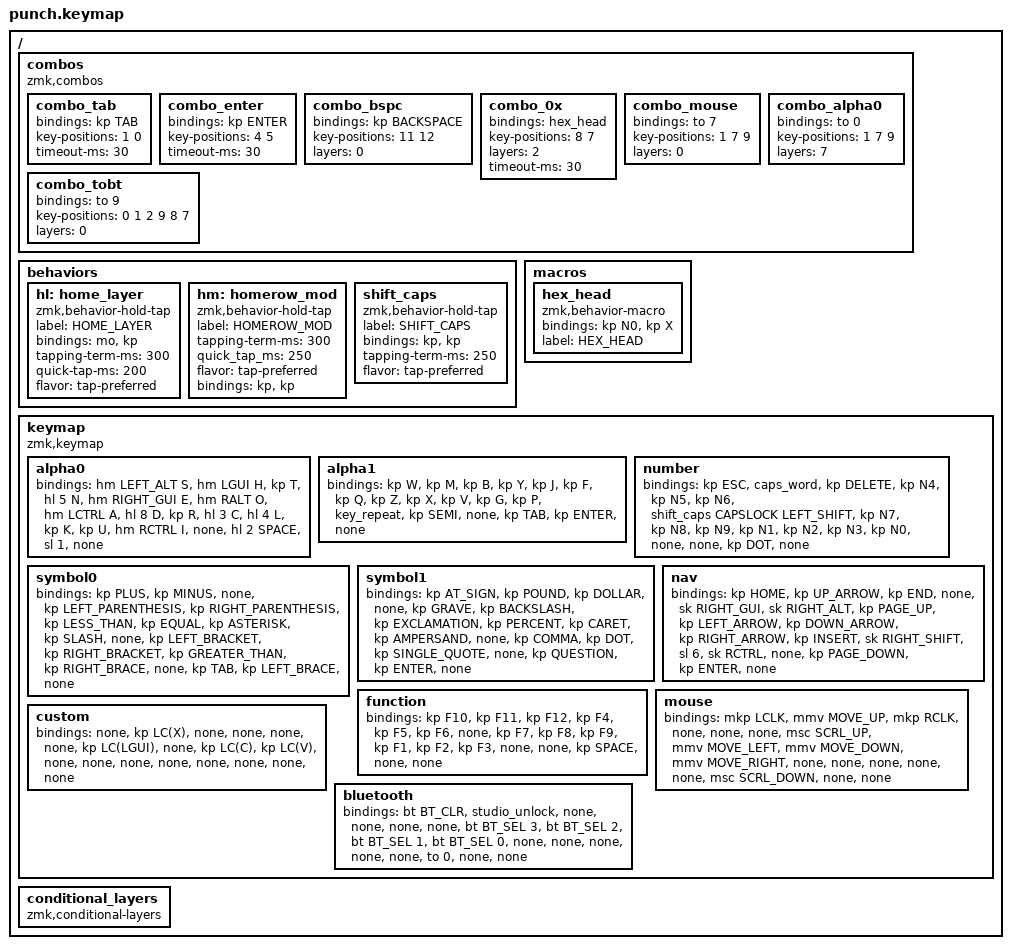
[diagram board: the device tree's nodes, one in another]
// This file was generated from a template. Edit it to match your keyboard.
// See https://zmk.dev/docs/development/hardware-integration/new-shield for more instructions.

#include <behaviors.dtsi>
#include <dt-bindings/zmk/bt.h>
#include <dt-bindings/zmk/keys.h>
#include <dt-bindings/zmk/pointing.h>

/* layers */

#define ALP0 0
#define ALP1 1
#define NUM  2
#define SYM0 3
#define SYM1 4
#define SYS  5
#define FUNC 6
#define MUS  7
#define CUS  8
#define BT   9

/ {
    // Define a default keymap here.
    // See https://zmk.dev/docs/development/hardware-integration/new-shield#default-keymap.

    combos {
        compatible = "zmk,combos";

        combo_tab {
            bindings = <&kp TAB>;
            key-positions = <1 0>;
            timeout-ms = <30>;
        };

        combo_enter {
            bindings = <&kp ENTER>;
            key-positions = <4 5>;
            timeout-ms = <30>;
        };

        combo_bspc {
            bindings = <&kp BACKSPACE>;
            key-positions = <11 12>;
            layers = <0>;
        };

        combo_0x {
            bindings = <&hex_head>;
            key-positions = <8 7>;
            layers = <2>;
            timeout-ms = <30>;
        };

        combo_mouse {
            bindings = <&to 7>;
            key-positions = <1 7 9>;
            layers = <0>;
        };

        combo_alpha0 {
            bindings = <&to 0>;
            key-positions = <1 7 9>;
            layers = <7>;
        };

        combo_tobt {
            bindings = <&to 9>;
            key-positions = <0 1 2 9 8 7>;
            layers = <0>;
        };
    };

    behaviors {
        hl: home_layer {
            compatible = "zmk,behavior-hold-tap";
            label = "HOME_LAYER";
            bindings = <&mo>, <&kp>;

            #binding-cells = <2>;
            tapping-term-ms = <300>;
            quick-tap-ms = <200>;
            flavor = "tap-preferred";
        };

        hm: homerow_mod {
            compatible = "zmk,behavior-hold-tap";
            label = "HOMEROW_MOD";
            #binding-cells = <2>;
            tapping-term-ms = <300>;
            quick_tap_ms = <250>;
            flavor = "tap-preferred";
            bindings = <&kp>, <&kp>;
        };

        shift_caps: shift_caps {
            compatible = "zmk,behavior-hold-tap";
            label = "SHIFT_CAPS";
            bindings = <&kp>, <&kp>;

            #binding-cells = <2>;
            tapping-term-ms = <250>;
            flavor = "tap-preferred";
        };
    };

    macros {
        hex_head: hex_head {
            compatible = "zmk,behavior-macro";
            #binding-cells = <0>;
            bindings = <&kp N0 &kp X>;
            label = "HEX_HEAD";
        };
    };

    keymap {
        compatible = "zmk,keymap";

        alpha0 {
            bindings = <
&hm LEFT_ALT S  &hm LGUI H  &kp T  &hl 5 N  &hm RIGHT_GUI E  &hm RALT O  &hm LCTRL A  &hl 8 D  &kp R  &hl 3 C  &hl 4 L  &kp K  &kp U  &hm RCTRL I  &none  &hl 2 SPACE  &sl 1  &none
            >;
        };

        alpha1 {
            bindings = <
&kp W  &kp M  &kp B  &kp Y  &kp J  &kp F  &kp Q  &kp Z  &kp X  &kp V  &kp G  &kp P  &key_repeat  &kp SEMI  &none  &kp TAB  &kp ENTER  &none
            >;
        };

        number {
            bindings = <
&kp ESC  &caps_word  &kp DELETE  &kp N4  &kp N5  &kp N6  &shift_caps CAPSLOCK LEFT_SHIFT  &kp N7  &kp N8  &kp N9  &kp N1  &kp N2  &kp N3  &kp N0  &none  &none  &kp DOT  &none
            >;
        };

        symbol0 {
            bindings = <
&kp PLUS  &kp MINUS  &none  &kp LEFT_PARENTHESIS  &kp RIGHT_PARENTHESIS  &kp LESS_THAN  &kp EQUAL  &kp ASTERISK  &kp SLASH  &none  &kp LEFT_BRACKET  &kp RIGHT_BRACKET  &kp GREATER_THAN  &kp RIGHT_BRACE  &none  &kp TAB  &kp LEFT_BRACE  &none
            >;
        };

        symbol1 {
            bindings = <
&kp AT_SIGN  &kp POUND  &kp DOLLAR  &none  &kp GRAVE  &kp BACKSLASH  &kp EXCLAMATION  &kp PERCENT  &kp CARET  &kp AMPERSAND  &none  &kp COMMA  &kp DOT  &kp SINGLE_QUOTE  &none  &kp QUESTION  &kp ENTER  &none
            >;
        };

        nav {
            bindings = <
&kp HOME  &kp UP_ARROW  &kp END  &none  &sk RIGHT_GUI  &sk RIGHT_ALT  &kp PAGE_UP  &kp LEFT_ARROW  &kp DOWN_ARROW  &kp RIGHT_ARROW  &kp INSERT  &sk RIGHT_SHIFT  &sl 6  &sk RCTRL  &none  &kp PAGE_DOWN  &kp ENTER  &none
            >;
        };

        function {
            bindings = <
&kp F10  &kp F11  &kp F12  &kp F4  &kp F5  &kp F6  &none  &kp F7  &kp F8  &kp F9  &kp F1  &kp F2  &kp F3  &none  &none  &kp SPACE  &none  &none
            >;
        };

        mouse {
            bindings = <
&mkp LCLK  &mmv MOVE_UP  &mkp RCLK  &none  &none  &none  &msc SCRL_UP  &mmv MOVE_LEFT  &mmv MOVE_DOWN  &mmv MOVE_RIGHT  &none  &none  &none  &none  &none  &msc SCRL_DOWN  &none  &none
            >;
        };

        custom {
            bindings = <
&none  &kp LC(X)  &none  &none  &none  &none  &kp LC(LGUI)  &none  &kp LC(C)  &kp LC(V)  &none  &none  &none  &none  &none  &none  &none  &none
            >;
        };

        bluetooth {
            bindings = <
&bt BT_CLR  &studio_unlock  &none  &none  &none  &none  &bt BT_SEL 3  &bt BT_SEL 2  &bt BT_SEL 1  &bt BT_SEL 0  &none  &none  &none  &none  &none  &to 0  &none  &none
            >;
        };
    };

    conditional_layers { compatible = "zmk,conditional-layers"; };
};
